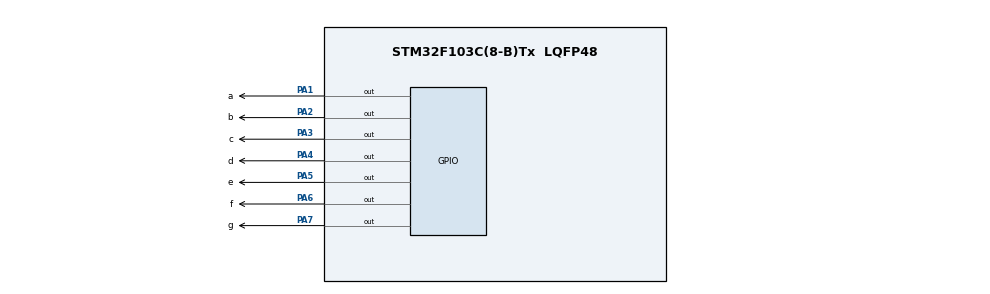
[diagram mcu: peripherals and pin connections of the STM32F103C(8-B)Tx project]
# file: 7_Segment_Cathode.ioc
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Mcu.Family=STM32F1
Mcu.Name=STM32F103C(8-B)Tx
Mcu.Package=LQFP48
NVIC.PriorityGroup=NVIC_PRIORITYGROUP_4
PA1.GPIO_Label=a
PA1.Signal=GPIO_Output
PA13.Mode=Serial_Wire
PA13.Signal=SYS_JTMS-SWDIO
PA14.Mode=Serial_Wire
PA14.Signal=SYS_JTCK-SWCLK
PA2.GPIO_Label=b
PA2.Signal=GPIO_Output
PA3.GPIO_Label=c
PA3.Signal=GPIO_Output
PA4.GPIO_Label=d
PA4.Signal=GPIO_Output
PA5.GPIO_Label=e
PA5.Signal=GPIO_Output
PA6.GPIO_Label=f
PA6.Signal=GPIO_Output
PA7.GPIO_Label=g
PA7.Signal=GPIO_Output
PD0-OSC_IN.Mode=HSE-External-Oscillator
PD0-OSC_IN.Signal=RCC_OSC_IN
PD1-OSC_OUT.Mode=HSE-External-Oscillator
PD1-OSC_OUT.Signal=RCC_OSC_OUT
ProjectManager.HeapSize=0x200
ProjectManager.StackSize=0x400
ProjectManager.TargetToolchain=STM32CubeIDE
RCC.APB1Freq_Value=8000000
RCC.APB2Freq_Value=8000000
board=custom

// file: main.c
/* USER CODE BEGIN Header */
/**
  ******************************************************************************
  * @file           : main.c
  * @brief          : Main program body
  ******************************************************************************
  * @attention
  *
  * Copyright (c) 2025 STMicroelectronics.
  * All rights reserved.
  *
  * This software is licensed under terms that can be found in the LICENSE file
  * in the root directory of this software component.
  * If no LICENSE file comes with this software, it is provided AS-IS.
  *
  ******************************************************************************
  */
/* USER CODE END Header */
#include "main.h"

/* USER CODE BEGIN PV */
/* USER CODE BEGIN PV */
char numbers[10] = {0x3F, 0x06, 0x5B, 0x4F, 0x66, 0x6D, 0x7D, 0x07, 0x7F, 0x6F};
/* USER CODE END PV */

/* USER CODE END PV */

void SystemClock_Config(void);
static void MX_GPIO_Init(void);
/* USER CODE BEGIN PFP */
/* USER CODE BEGIN PFP */
void SevSeg(char num) {
	HAL_GPIO_WritePin(a_GPIO_Port, a_Pin, num & 1);
	HAL_GPIO_WritePin(b_GPIO_Port, b_Pin, (num >> 1) & 1);
	HAL_GPIO_WritePin(c_GPIO_Port, c_Pin, (num >> 2) & 1);
	HAL_GPIO_WritePin(d_GPIO_Port, d_Pin, (num >> 3) & 1);
	HAL_GPIO_WritePin(e_GPIO_Port, e_Pin, (num >> 4) & 1);
	HAL_GPIO_WritePin(f_GPIO_Port, f_Pin, (num >> 5) & 1);
	HAL_GPIO_WritePin(g_GPIO_Port, g_Pin, (num >> 6) & 1);
}
/* USER CODE END PFP */

/* USER CODE END PFP */

int main(void)
{

  /* MCU Configuration--------------------------------------------------------*/

  /* Reset of all peripherals, Initializes the Flash interface and the Systick. */
  HAL_Init();

  /* Configure the system clock */
  SystemClock_Config();

  /* Initialize all configured peripherals */
  MX_GPIO_Init();

  /* Infinite loop */
  /* USER CODE BEGIN WHILE */
  while (1)
  {
	  for(uint8_t i = 0; i < 10; i++) {
	  		  SevSeg(numbers[i]);
	  		  HAL_Delay(1000);
	  }

	  }

    /* USER CODE END WHILE */

  }

void SystemClock_Config(void)
{
  RCC_OscInitTypeDef RCC_OscInitStruct = {0};
  RCC_ClkInitTypeDef RCC_ClkInitStruct = {0};

  /** Initializes the RCC Oscillators according to the specified parameters
  * in the RCC_OscInitTypeDef structure.
  */
  RCC_OscInitStruct.OscillatorType = RCC_OSCILLATORTYPE_HSI;
  RCC_OscInitStruct.HSIState = RCC_HSI_ON;
  RCC_OscInitStruct.HSICalibrationValue = RCC_HSICALIBRATION_DEFAULT;
  RCC_OscInitStruct.PLL.PLLState = RCC_PLL_NONE;
  if (HAL_RCC_OscConfig(&RCC_OscInitStruct) != HAL_OK)
  {
    Error_Handler();
  }

  /** Initializes the CPU, AHB and APB buses clocks
  */
  RCC_ClkInitStruct.ClockType = RCC_CLOCKTYPE_HCLK|RCC_CLOCKTYPE_SYSCLK
                              |RCC_CLOCKTYPE_PCLK1|RCC_CLOCKTYPE_PCLK2;
  RCC_ClkInitStruct.SYSCLKSource = RCC_SYSCLKSOURCE_HSI;
  RCC_ClkInitStruct.AHBCLKDivider = RCC_SYSCLK_DIV1;
  RCC_ClkInitStruct.APB1CLKDivider = RCC_HCLK_DIV1;
  RCC_ClkInitStruct.APB2CLKDivider = RCC_HCLK_DIV1;

  if (HAL_RCC_ClockConfig(&RCC_ClkInitStruct, FLASH_LATENCY_0) != HAL_OK)
  {
    Error_Handler();
  }
}

static void MX_GPIO_Init(void)
{
  GPIO_InitTypeDef GPIO_InitStruct = {0};

  /* GPIO Ports Clock Enable */
  __HAL_RCC_GPIOD_CLK_ENABLE();
  __HAL_RCC_GPIOA_CLK_ENABLE();

  /*Configure GPIO pin Output Level */
  HAL_GPIO_WritePin(GPIOA, a_Pin|b_Pin|c_Pin|d_Pin
                          |e_Pin|f_Pin|g_Pin, GPIO_PIN_RESET);

  /*Configure GPIO pins : a_Pin b_Pin c_Pin d_Pin
                           e_Pin f_Pin g_Pin */
  GPIO_InitStruct.Pin = a_Pin|b_Pin|c_Pin|d_Pin
                          |e_Pin|f_Pin|g_Pin;
  GPIO_InitStruct.Mode = GPIO_MODE_OUTPUT_PP;
  GPIO_InitStruct.Pull = GPIO_NOPULL;
  GPIO_InitStruct.Speed = GPIO_SPEED_FREQ_LOW;
  HAL_GPIO_Init(GPIOA, &GPIO_InitStruct);

}

void Error_Handler(void)
{
  __disable_irq();
  while (1)
  {
  }
}
